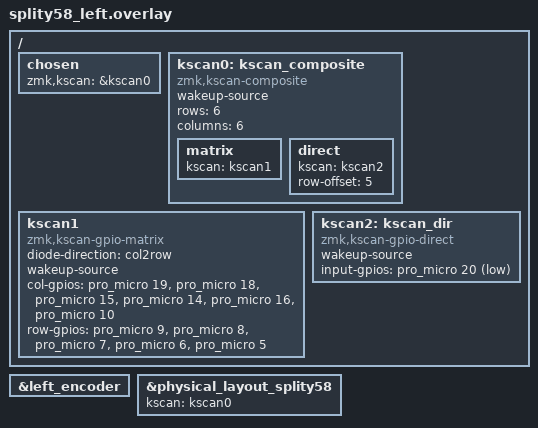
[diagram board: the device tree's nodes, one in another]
#include "splity58.dtsi"

/ {
    chosen {
        zmk,kscan = &kscan0;
    };

    kscan0: kscan_composite {
        compatible = "zmk,kscan-composite";
        wakeup-source;
        rows = <6>;
        columns = <6>;

        // Include the matrix driver
        matrix {
            kscan = <&kscan1>;
        };

        // Include the direct GPIO driver...
        direct {
            kscan = <&kscan2>;
            row-offset = <5>; // ...and shift it to not overlap
        };
    };

    kscan1: kscan1 {
        compatible = "zmk,kscan-gpio-matrix";
        diode-direction = "col2row";
        wakeup-source;

        col-gpios
            = <&pro_micro 19 GPIO_ACTIVE_HIGH>
            , <&pro_micro 18 GPIO_ACTIVE_HIGH>
            , <&pro_micro 15 GPIO_ACTIVE_HIGH>
            , <&pro_micro 14 GPIO_ACTIVE_HIGH>
            , <&pro_micro 16 GPIO_ACTIVE_HIGH>
            , <&pro_micro 10 GPIO_ACTIVE_HIGH>
            ;

        row-gpios
            = <&pro_micro 9 (GPIO_ACTIVE_HIGH | GPIO_PULL_DOWN)>
            , <&pro_micro 8 (GPIO_ACTIVE_HIGH | GPIO_PULL_DOWN)>
            , <&pro_micro 7 (GPIO_ACTIVE_HIGH | GPIO_PULL_DOWN)>
            , <&pro_micro 6 (GPIO_ACTIVE_HIGH | GPIO_PULL_DOWN)>
            , <&pro_micro 5 (GPIO_ACTIVE_HIGH | GPIO_PULL_DOWN)>
            ;
    }; 

    kscan2: kscan_dir {
        compatible = "zmk,kscan-gpio-direct";
        wakeup-source;
        input-gpios
            = <&pro_micro 20 (GPIO_ACTIVE_LOW | GPIO_PULL_UP)>;
    };

    
};

&left_encoder {
        status = "okay";
    };

&physical_layout_splity58 {
    kscan = <&kscan0>;
};
